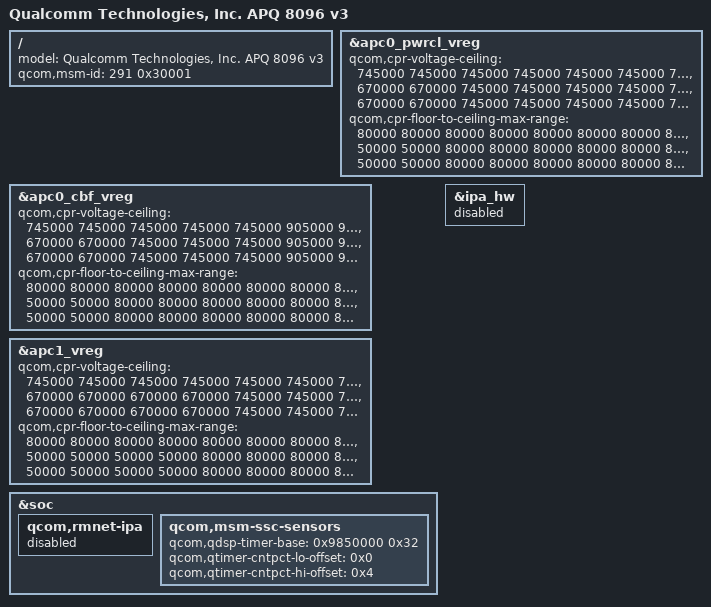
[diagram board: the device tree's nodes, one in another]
/* Copyright (c) 2014-2016, The Linux Foundation. All rights reserved.
 *
 * This program is free software; you can redistribute it and/or modify
 * it under the terms of the GNU General Public License version 2 and
 * only version 2 as published by the Free Software Foundation.
 *
 * This program is distributed in the hope that it will be useful,
 * but WITHOUT ANY WARRANTY; without even the implied warranty of
 * MERCHANTABILITY or FITNESS FOR A PARTICULAR PURPOSE.  See the
 * GNU General Public License for more details.
 */

/*
 * As a general rule, only version-specific property overrides should be placed
 * inside this file. Common device definitions should be placed inside the
 * msm8996.dtsi file.
 */

#include "msm8996-v3.dtsi"

/ {
	model = "Qualcomm Technologies, Inc. APQ 8096 v3";
	qcom,msm-id = <291 0x30001>;
};

&apc0_pwrcl_vreg {
	qcom,cpr-voltage-ceiling =
					/* Speed bin 0 */
					<745000  745000  745000  745000  745000
					 745000  745000  905000  905000  905000
					 905000  905000 1140000 1140000 1140000
					1140000>,

					/* Speed bin 1 */
					<670000  670000  745000  745000  745000
					 745000  745000  905000  905000  905000
					 905000  905000 1140000>,

					/* Speed bin 2 */
					<670000  670000  745000  745000  745000
					 745000  745000  905000  905000  905000
					 905000  905000 1140000 1140000 1140000
					1140000>;

	qcom,cpr-floor-to-ceiling-max-range =
					/* Speed bin 0 */
					 <80000   80000   80000   80000   80000
					  80000   80000   80000   80000   80000
					  80000   80000   80000   80000   80000
					  80000>,

					/* Speed bin 1 */
					 <50000   50000   80000   80000   80000
					  80000   80000   80000   80000   80000
					  80000   80000   80000>,

					/* Speed bin 2 */
					 <50000   50000   80000   80000   80000
					  80000   80000   80000   80000   80000
					  80000   80000   80000   80000   80000
					  80000>;

};

&apc0_cbf_vreg {
	qcom,cpr-voltage-ceiling =
				       /* Speed bin 0 */
				       <745000  745000  745000  745000  745000
					905000  905000  905000  905000  905000
					905000  905000  905000 1140000 1140000
				       1140000 1140000 1140000 1140000>,

				       /* Speed bin 1 */
				       <670000  670000  745000  745000  745000
					905000  905000  905000  905000  905000
					905000  905000  905000 1140000 1140000>,

				       /* Speed bin 2 */
				       <670000  670000  745000  745000  745000
					905000  905000  905000  905000  905000
					905000  905000  905000 1140000 1140000
				       1140000 1140000 1140000 1140000>;

	qcom,cpr-floor-to-ceiling-max-range =
					/* Speed bin 0 */
					<80000   80000   80000   80000   80000
					 80000   80000   80000   80000   80000
					 80000   80000   80000   80000   80000
					 80000   80000   80000   80000>,

					/* Speed bin 1 */
					<50000   50000   80000   80000   80000
					 80000   80000   80000   80000   80000
					 80000   80000   80000   80000   80000>,

					/* Speed bin 2 */
					<50000   50000   80000   80000   80000
					 80000   80000   80000   80000   80000
					 80000   80000   80000   80000   80000
					 80000   80000   80000   80000>;

};

&apc1_vreg {
	qcom,cpr-voltage-ceiling =
				       /* Speed bin 0 */
				       <745000  745000  745000  745000  745000
					745000  745000  745000  745000  905000
					905000  905000  905000 1140000 1140000
				       1140000 1140000 1140000 1140000 1140000
				       1140000 1140000 1140000 1140000 1140000>,

				       /* Speed bin 1 */
				       <670000  670000  670000  670000  745000
					745000  745000  745000  745000  905000
					905000  905000  905000 1140000 1140000
				       1140000 1140000 1140000 1140000 1140000
				       1140000>,

				       /* Speed bin 2 */
				       <670000  670000  670000  670000  745000
					745000  745000  745000  745000  905000
					905000  905000  905000 1140000 1140000
				       1140000 1140000 1140000 1140000 1140000
				       1140000 1140000 1140000 1140000 1140000>;

	qcom,cpr-floor-to-ceiling-max-range =
					/* Speed bin 0 */
					<80000   80000   80000   80000   80000
					 80000   80000   80000   80000   80000
					 80000   80000   80000   80000   80000
					 80000   80000   80000   80000   80000
					 80000   80000   80000   80000   80000>,

					/* Speed bin 1 */
					<50000   50000   50000   50000   80000
					 80000   80000   80000   80000   80000
					 80000   80000   80000   80000   80000
					 80000   80000   80000   80000   80000
					 80000>,

					/* Speed bin 2 */
					<50000   50000   50000   50000   80000
					 80000   80000   80000   80000   80000
					 80000   80000   80000   80000   80000
					 80000   80000   80000   80000   80000
					 80000   80000   80000   80000   80000>;

};

&soc {
	qcom,rmnet-ipa {
		status = "disabled";
	};

	qcom,msm-ssc-sensors {
		qcom,qdsp-timer-base = <0x9850000 0x32>;
		qcom,qtimer-cntpct-lo-offset = <0x0>;
		qcom,qtimer-cntpct-hi-offset = <0x4>;
	};
};

&ipa_hw {
	status = "disabled";
};
